# Nintendo_64 register map
File version: 1.0
Nintendo 64 system SVD file for the VR4300 CPU
CPU: OTHER r1p0, big endian, no MPU, FPU, 8 interrupt priority bits
Address unit: 32 bits
Registers are 32-bit, read-write, no defined reset value unless marked. A register's access mark holds for its fields unless they carry their own. Offsets are from the block's base; lines under a group give offsets from that group; [hi:lo] are bit positions; {n}, {i} and the like mark numbered series; 'fields as' and 'values as' point back to an identical list; <NAME> marks a mode.

## Memory map
0xA4040000 SP size 0x3C — Signal Processor (RSP)
0xA4300000 MI size 0x2C — MIPS Interface Controller
0xA4600000 PI size 0x50 — Peripheral Interface
0xA4800000 SI size 0x38 — Serial Interface

## MI — MIPS Interface Controller
Base 0xA4300000
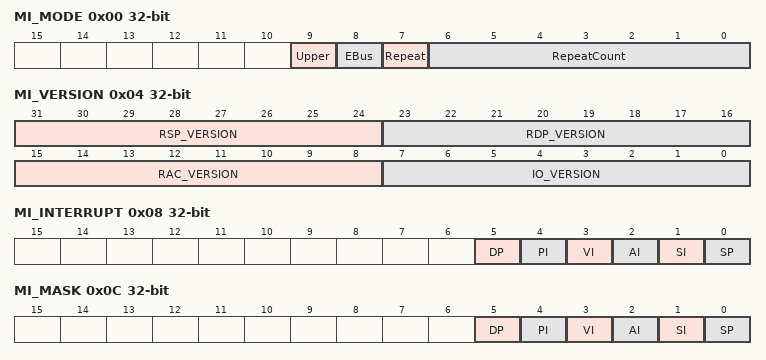
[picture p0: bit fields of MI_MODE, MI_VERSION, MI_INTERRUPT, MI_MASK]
0x00 MI_MODE
  [9] Upper — Upper mode enabled
  [8] EBus — EBus mode enabled
  [7] Repeat — Repeat mode enabled
  [6:0] RepeatCount — Number of bytes (minus 1) to write in repeat mode
0x04 MI_VERSION ro
  [31:24] RSP_VERSION — RSP hardware version
  [23:16] RDP_VERSION — RDP hardware version
  [15:8] RAC_VERSION — RAC hardware version
  [7:0] IO_VERSION — IO hardware version
0x08 MI_INTERRUPT
  [5] DP — DP Interrupt Mask
  [4] PI — PI Interrupt Mask
  [3] VI — VI Interrupt Mask
  [2] AI — AI Interrupt Mask
  [1] SI — SI Interrupt Mask
  [0] SP — SP Interrupt Mask
0x0C MI_MASK
  fields as MI_INTERRUPT

## SI — Serial Interface
Base 0xA4800000
0x00 SI_DRAM_ADDR — Serial Interface DRAM Address
  [23:0] DRAM_ADDR — RDRAM address used in SI DMAs
0x04 SI_PIF_AD_RD64B ro — Serial Interface PIF Address Read (64-bit)
  [10:0] PIF_ADDR — Offset in PIF_RAM/PIF_ROM where to fetch data
0x08 SI_PIF_AD_WR4B — Serial Interface PIF Address Write (4-byte)
  [31:0] DATA — 32-bit data to be transferred to PIF-RAM
0x10 SI_PIF_AD_WR64B — Serial Interface PIF Address Write (64-bit)
  [31:0] Unknown
0x14 SI_PIF_AD_RD4B ro — Serial Interface PIF Address Read (4-byte)
  [31:0] DATA — 32-bit data to be transferred to PIF-RAM
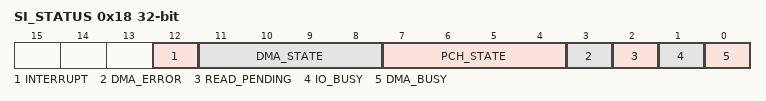
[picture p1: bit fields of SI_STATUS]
0x18 SI_STATUS — Serial Interface Status Register
  [12] INTERRUPT — SI interrupt flag
  [11:8] DMA_STATE — Internal DMA state
  [7:4] PCH_STATE — Internal PIF channel state
  [3] DMA_ERROR — Set when overlapping DMA occurs
  [2] READ_PENDING
  [1] IO_BUSY — Set when a direct memory write to PIF_RAM is in progress
  [0] DMA_BUSY — Set when a DMA is in progress

## SP — Signal Processor (RSP)
Base 0xA4040000
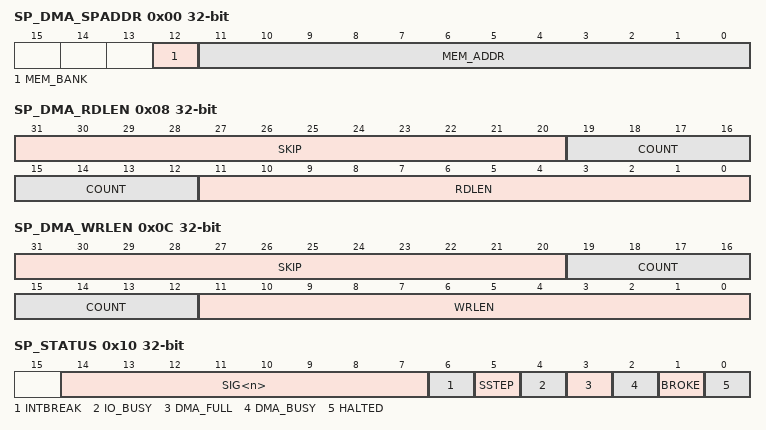
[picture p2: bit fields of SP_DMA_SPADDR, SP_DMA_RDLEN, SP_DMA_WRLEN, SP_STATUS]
0x00 SP_DMA_SPADDR — Address in IMEM/DMEM for a DMA transfer
  [12] MEM_BANK — Bank accessed by the transfer
  [11:0] MEM_ADDR — DMEM or IMEM address used in SP DMAs
0x04 SP_DMA_RAMADDR — Address in RDRAM for a DMA transfer
  [23:0] DRAM_ADDR — RDRAM address used in the DMA transfer
0x08 SP_DMA_RDLEN — Length of a DMA transfer. Writing this register triggers a DMA transfer from RDRAM to IMEM/DMEM
  [31:20] SKIP — Number of bytes to skip in RDRAM after each row
  [19:12] COUNT — Number of rows to transfer minus 1
  [11:0] RDLEN — Number of bytes to transfer for each row minus 1
0x0C SP_DMA_WRLEN — Length of a DMA transfer. Writing this register triggers a DMA transfer from IMEM/DMEM to RDRAM
  [31:20] SKIP — Number of bytes to skip in RDRAM after each row
  [19:12] COUNT — Number of rows to transfer minus 1
  [11:0] WRLEN — Number of bytes to transfer for each row minus 1
0x10 SP_STATUS — RSP status register
  [14:7] SIG<n> — Status of the 8 custom bits that can be freely used to communicate state between VR4300 and RSP
  [6] INTBREAK — Trigger an MI interrupt when BREAK is run
  [5] SSTEP — Single-step mode activated
  [4] IO_BUSY — RSP accessing either DMEM or IMEM
  [3] DMA_FULL — DMA transfer pending flag
  [2] DMA_BUSY — DMA transfer in progress flag
  [1] BROKE — BREAK opcode executed
  [0] HALTED — RSP running status
0x14 SP_DMA_FULL — Report whether there is a pending DMA transfer (mirror of DMA_FULL bit of SP_STATUS)
  [0] DMA_FULL — Mirror of DMA_FULL bit in SP_STATUS
0x18 SP_DMA_BUSY — Report whether there is a DMA transfer in progress (mirror of DMA_BUSY bit of SP_STATUS)
  [0] DMA_BUSY — Mirror of DMA_BUSY bit in SP_STATUS
0x1C SP_SEMAPHORE — Register to assist implementing a simple mutex between VR4300 and RSP
  [0] SEMAPHORE — Semaphore bit for hardware-assisted mutex

## PI — Peripheral Interface
Base 0xA4600000
0x00 PI_DRAM_ADDR — Base address of RDRAM for PI DMAs
  [23:1] DRAM_ADDR
0x04 PI_CART_ADDR — Base address of the PI bus for PI DMAs
  [31:1] CART_ADDR
0x08 PI_RD_LEN — Number of bytes, minus one, to be transferred from RDRAM to the PI bus
  [23:0] RD_LEN
0x0C PI_WR_LEN — Number of bytes, minus one, to be transferred from the PI bus, into RDRAM
  [23:0] WR_LEN
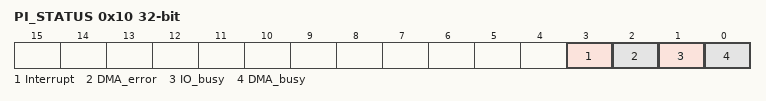
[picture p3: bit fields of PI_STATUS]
0x10 PI_STATUS — Status of the PI
  [3] Interrupt — DMA completed
  [2] DMA_error
  [1] IO_busy
  [0] DMA_busy — DMA is busy
0x14 PI_BSD_DOM1_LAT — Latency value for DOM1
  [7:0] LAT — Number of RCP cycles, minus one, before the first read or write may start
0x18 PI_BSD_DOM1_PWD — Pulse width value for DOM1
  [7:0] PWD — Number of RCP cycles, minus one, the /RD or /WR signals are held low
0x1C PI_BSD_DOM1_PGS — Page size value for DOM1
  [3:0] PGS — Number of bytes that can be sequentially read/written on the bus before sending the next base address
0x20 PI_BSD_DOM1_RLS — Release value for DOM1
  [1:0] RLS — Number of RCP cycles, minus one, that the /RD or /WR signals are held high between each 16-bits of data
0x24 PI_BSD_DOM2_LAT — Latency value for DOM2
  fields as PI_BSD_DOM1_LAT
0x28 PI_BSD_DOM2_PWD — Pulse width value for DOM2
  fields as PI_BSD_DOM1_PWD
0x2C PI_BSD_DOM2_PGS — Page size value for DOM2
  fields as PI_BSD_DOM1_PGS
0x30 PI_BSD_DOM2_RLS — Release value for DOM2
  fields as PI_BSD_DOM1_RLS
